# FM33A0XXEV register map
File version: 1.0
CPU: SC000, little endian, no MPU, no FPU, 3 interrupt priority bits
Registers are 32-bit, read-write, reset 0x0 unless marked. A register's access mark holds for its fields unless they carry their own. Offsets are from the block's base; [hi:lo] are bit positions; {n}, {i} and the like mark numbered series.

## DBG — DBG module information
Base 0x40000000
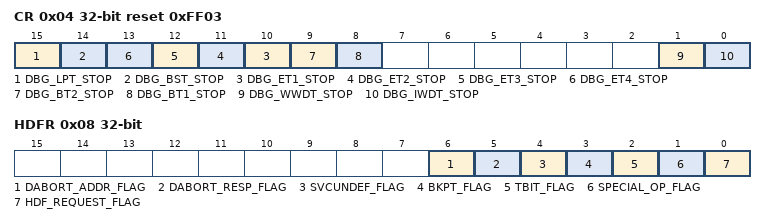
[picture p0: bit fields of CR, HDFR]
0x04 CR reset 0xFF03 — Debug Configuration Register
  [15] DBG_LPT_STOP — DBG_LPT_STOP field description
  [14] DBG_BST_STOP — DBG_BST_STOP field description
  [n+9] DBG_ET{n}_STOP (n=1..4) — DBG_ET{n}_STOP field description
  [9] DBG_BT2_STOP — DBG_BT2_STOP field description
  [8] DBG_BT1_STOP — DBG_BT1_STOP field description
  [1] DBG_WWDT_STOP — DBG_WWDT_STOP field description
  [0] DBG_IWDT_STOP — DBG_IWDT_STOP field description
0x08 HDFR — HardFault Flag Register
  [6] DABORT_ADDR_FLAG — DABORT_ADDR_FLAG field description
  [5] DABORT_RESP_FLAG — DABORT_RESP_FLAG field description
  [4] SVCUNDEF_FLAG — SVCUNDEF_FLAG field description
  [3] BKPT_FLAG — BKPT_FLAG field description
  [2] TBIT_FLAG — TBIT_FLAG field description
  [1] SPECIAL_OP_FLAG — SPECIAL_OP_FLAG field description
  [0] HDF_REQUEST_FLAG — HDF_REQUEST_FLAG field description

## FLS — FLS module information
Base 0x40001000
0x00 RDCR — Flash Read Control Register
  [1:0] WAIT — WAIT field description
0x04 PFCR — Flash Prefetch Control Register
  [0] PRFTEN — PRFTEN field description
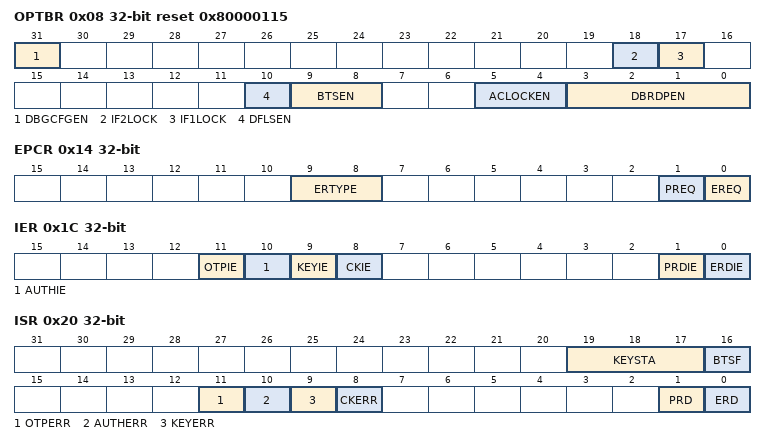
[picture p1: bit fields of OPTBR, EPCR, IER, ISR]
0x08 OPTBR reset 0x80000115 — Flash Option Bytes Register
  [31] DBGCFGEN ro — DBGCFGEN field description
  [18] IF2LOCK ro — IF2LOCK field description
  [17] IF1LOCK ro — IF1LOCK field description
  [10] DFLSEN ro — DFLSEN field description
  [9:8] BTSEN ro — BTSEN field description
  [5:4] ACLOCKEN ro — ACLOCKEN field description
  [3:0] DBRDPEN ro — DBRDPEN field description
0x14 EPCR — Flash Erase/Program Control Register
  [9:8] ERTYPE — ERTYPE field description
  [1] PREQ — PREQ field description
  [0] EREQ — EREQ field description
0x18 KEY — Flash Key Register
  [31:0] KEY wo — KEY field description
0x1C IER — Flash Interrupt Enable Register
  [11] OTPIE — OTPIE field description
  [10] AUTHIE — AUTHIE field description
  [9] KEYIE — KEYIE field description
  [8] CKIE — CKIE field description
  [1] PRDIE — PRDIE field description
  [0] ERDIE — ERDIE field description
0x20 ISR — Flash Interrupt Status Register
  [19:17] KEYSTA ro — KEYSTA field description
  [16] BTSF ro — BTSF field description
  [11] OTPERR — OTPERR field description
  [10] AUTHERR — AUTHERR field description
  [9] KEYERR — KEYERR field description
  [8] CKERR — CKERR field description
  [1] PRD — PRD field description
  [0] ERD — ERD field description
0x48 ACLOCK1 — Flash Application Code Lock Register1
  [31:0] LOCK1 — LOCK1 field description
0x4C ACLOCK2 — Flash Application Code Lock Register2
  [31:0] LOCK2 — LOCK2 field description
0x50 ACLOCK3 — Flash Application Code Lock Register1
  [31:0] LOCK3 — LOCK3 field description
0x54 ACLOCK4 — Flash Application Code Lock Register2
  [31:0] LOCK4 — LOCK4 field description

## RMU — RMU module information
Base 0x40002800
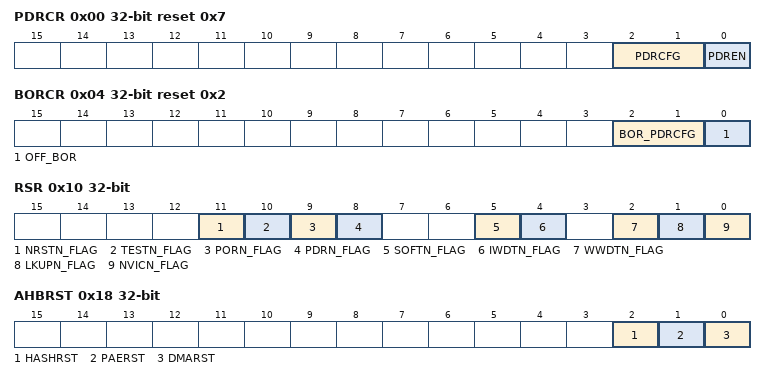
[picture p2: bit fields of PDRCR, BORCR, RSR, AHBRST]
0x00 PDRCR reset 0x7 — PDR Control Register
  [2:1] PDRCFG — PDRCFG field description
  [0] PDREN — PDREN field description
0x04 BORCR reset 0x2 — BOR Control Register
  [2:1] BOR_PDRCFG — BOR_PDRCFG field description
  [0] OFF_BOR — OFF_BOR field description
0x08 RSTCFGR — Reset Config Register
  [1] LKUPRST_EN — LKUPRST_EN field description
0x0C SOFTRST — Soft Reset Register
  [31:0] SOFTRST wo — SOFTRST field description
0x10 RSR — Reset Status Register
  [11] NRSTN_FLAG — NRSTN_FLAG field description
  [10] TESTN_FLAG — TESTN_FLAG field description
  [9] PORN_FLAG — PORN_FLAG field description
  [8] PDRN_FLAG — PDRN_FLAG field description
  [5] SOFTN_FLAG — SOFTN_FLAG field description
  [4] IWDTN_FLAG — IWDTN_FLAG field description
  [2] WWDTN_FLAG — WWDTN_FLAG field description
  [1] LKUPN_FLAG — LKUPN_FLAG field description
  [0] NVICN_FLAG — NVICN_FLAG field description
0x14 PRSTEN — Peripheral Reset Enable Register
  [31:0] PERHRSTEN wo — PERHRSTEN field description
0x18 AHBRST — AHB Peripheral Reset Register
  [2] HASHRST — HASHRST field description
  [1] PAERST — PAERST field description
  [0] DMARST — DMARST field description
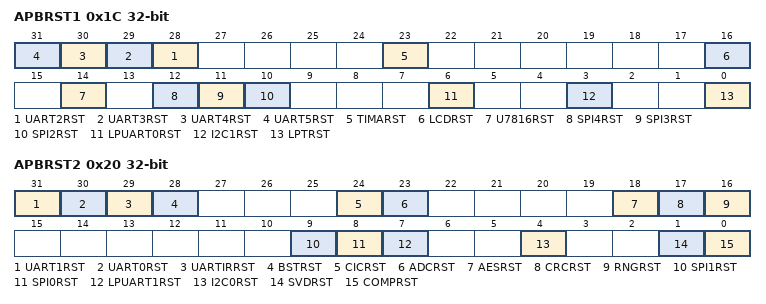
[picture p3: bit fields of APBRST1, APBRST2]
0x1C APBRST1 — APB Peripheral Reset Register1
  [n+26] UART{n}RST (n=2..5) — UART{n}RST field description
  [23] TIMARST — TIMARST field description
  [16] LCDRST — LCDRST field description
  [14] U7816RST — U7816RST field description
  [12] SPI4RST — SPI4RST field description
  [11] SPI3RST — SPI3RST field description
  [10] SPI2RST — SPI2RST field description
  [6] LPUART0RST — LPUART0RST field description
  [3] I2C1RST — I2C1RST field description
  [0] LPTRST — LPTRST field description
0x20 APBRST2 — APB Peripheral Reset Register2
  [31] UART1RST — UART1RST field description
  [30] UART0RST — UART0RST field description
  [29] UARTIRRST — UARTIRRST field description
  [28] BSTRST — BSTRST field description
  [24] CICRST — CICRST field description
  [23] ADCRST — ADCRST field description
  [18] AESRST — AESRST field description
  [17] CRCRST — CRCRST field description
  [16] RNGRST — RNGRST field description
  [9] SPI1RST — SPI1RST field description
  [8] SPI0RST — SPI0RST field description
  [7] LPUART1RST — LPUART1RST field description
  [4] I2C0RST — I2C0RST field description
  [1] SVDRST — SVDRST field description
  [0] COMPRST — COMPRST field description
